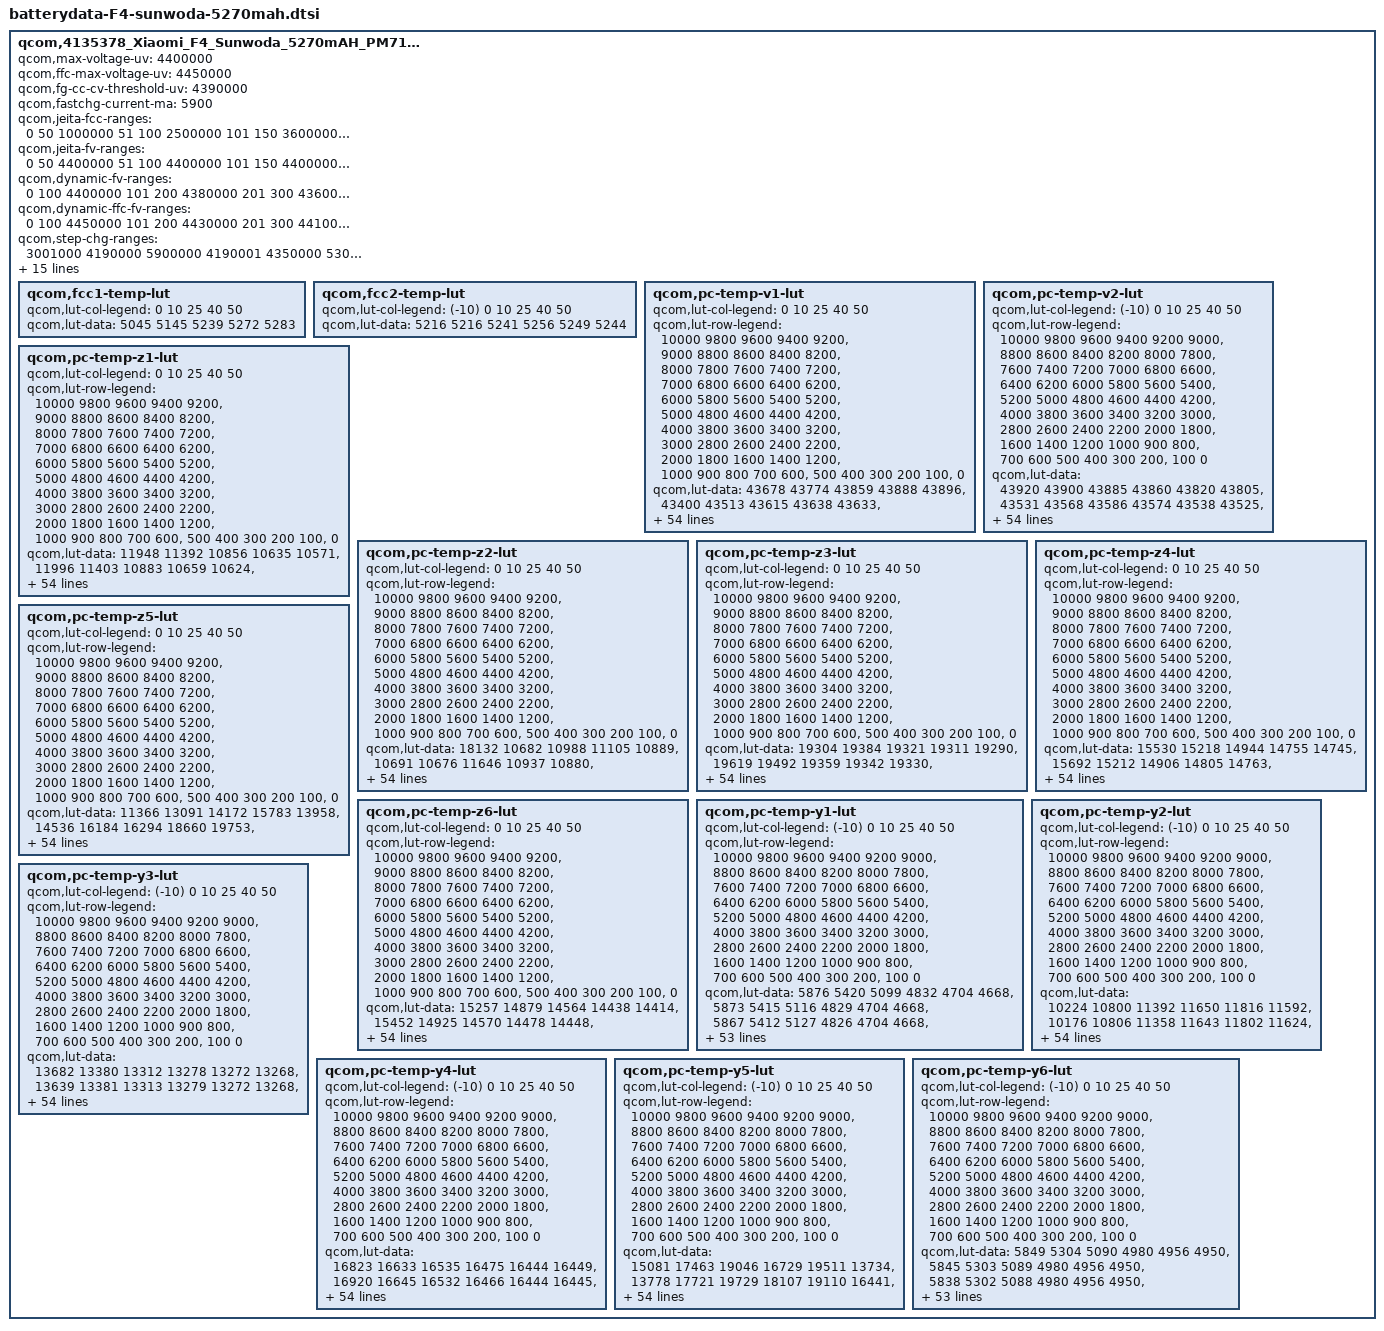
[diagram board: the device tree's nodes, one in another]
qcom,4135378_Xiaomi_F4_Sunwoda_5270mAH_PM7150 {
	/* 4135378_Xiaomi_F4_Sunwoda_5270mAH_PM7150_averaged_MasterSlave_Aug12th2019 */
	qcom,max-voltage-uv = <4400000>;
	qcom,ffc-max-voltage-uv = <4450000>;
	qcom,fg-cc-cv-threshold-uv = <4390000>;
	qcom,fastchg-current-ma = <5900>;
	qcom,jeita-fcc-ranges = <0  50   1000000
				51  100  2500000
				101 150  3600000
				151 480  5900000
				481 580  2800000>;
	qcom,jeita-fv-ranges = <0   50  4400000
				51  100  4400000
				101 150  4400000
				151 480  4450000
				481 580  4100000>;
	qcom,dynamic-fv-ranges = <0    100  4400000
				101  200  4380000
				201  300  4360000
				301  400  4340000
				401  500  4340000>;
	qcom,dynamic-ffc-fv-ranges = <0    100  4450000
				101  200  4430000
				201  300  4410000
				301  400  4390000
				401  500  4390000>;
	qcom,step-chg-ranges = <3001000  4190000  5900000
				4190001  4350000  5300000
				4350001  4390000  5300000
				4390001  4430000  4100000
				4430001  4480000  4100000>;
	qcom,temp-comp-ranges = <0    3899  0
				 3900 4599  2
				 4600 5599  5
				 5600 5749  6
				 5750 5900  6>;
	qcom,nom-batt-capacity-mah = <5260>;
	qcom,batt-id-kohm = <100>;
	qcom,battery-beta = <4250>;
	qcom,battery-therm-kohm = <100>;
	qcom,battery-type = "f4_swd";
	qcom,qg-batt-profile-ver = <100>;
	qcom,temp-comp-enable;
	qcom,temp-comp-hysteresis = <200>;
	qcom,max-temp-comp-value = <6>;
	mi,six-pin-battery;
	mi,use-bq-pump;
	mi,fcc-limited-by-soc;
	mi,ffc-iterm-change-by-temp;
	qcom,fcc1-temp-lut {
		qcom,lut-col-legend = <0 10 25 40 50>;
		qcom,lut-data = <5045 5145 5239 5272 5283>;
	};

	qcom,fcc2-temp-lut {
		qcom,lut-col-legend = <(-10) 0 10 25 40 50>;
		qcom,lut-data = <5216 5216 5241 5256 5249 5244>;
	};

	qcom,pc-temp-v1-lut {
		qcom,lut-col-legend = <0 10 25 40 50>;
		qcom,lut-row-legend = <10000 9800 9600 9400 9200>,
			<9000 8800 8600 8400 8200>,
			<8000 7800 7600 7400 7200>,
			<7000 6800 6600 6400 6200>,
			<6000 5800 5600 5400 5200>,
			<5000 4800 4600 4400 4200>,
			<4000 3800 3600 3400 3200>,
			<3000 2800 2600 2400 2200>,
			<2000 1800 1600 1400 1200>,
			<1000 900 800 700 600>,
			<500 400 300 200 100>,
			<0>;
		qcom,lut-data = <43678 43774 43859 43888 43896>,
			<43400 43513 43615 43638 43633>,
			<43145 43263 43372 43392 43392>,
			<42901 43024 43132 43152 43155>,
			<42662 42788 42893 42918 42925>,
			<42431 42551 42655 42685 42697>,
			<42205 42318 42417 42451 42465>,
			<41985 42091 42181 42218 42233>,
			<41769 41871 41951 41989 42004>,
			<41558 41654 41726 41762 41775>,
			<41351 41437 41506 41539 41549>,
			<41152 41225 41291 41318 41328>,
			<40971 41030 41080 41101 41110>,
			<40790 40857 40877 40895 40903>,
			<40573 40678 40678 40697 40702>,
			<40309 40457 40481 40505 40509>,
			<40076 40213 40275 40308 40317>,
			<39915 40016 40081 40117 40132>,
			<39782 39873 39921 39944 39959>,
			<39651 39739 39787 39795 39803>,
			<39526 39580 39627 39635 39638>,
			<39399 39406 39394 39426 39433>,
			<39254 39223 39151 39199 39210>,
			<39094 39003 38978 39014 39024>,
			<38934 38799 38839 38858 38865>,
			<38765 38687 38719 38724 38727>,
			<38609 38618 38613 38610 38610>,
			<38513 38554 38519 38511 38508>,
			<38449 38486 38432 38419 38414>,
			<38398 38420 38352 38333 38325>,
			<38354 38360 38282 38257 38245>,
			<38317 38302 38216 38187 38172>,
			<38281 38250 38160 38125 38105>,
			<38247 38205 38112 38070 38046>,
			<38215 38166 38072 38025 37995>,
			<38183 38129 38032 37978 37942>,
			<38154 38098 37994 37926 37882>,
			<38116 38061 37953 37869 37817>,
			<38056 37999 37892 37801 37741>,
			<37977 37905 37805 37718 37652>,
			<37884 37804 37706 37622 37552>,
			<37769 37693 37596 37510 37442>,
			<37634 37564 37468 37381 37315>,
			<37473 37401 37308 37226 37151>,
			<37324 37251 37164 37084 37015>,
			<37237 37156 37068 36996 36937>,
			<37208 37130 37044 36969 36911>,
			<37181 37109 37028 36951 36894>,
			<37156 37088 37009 36933 36877>,
			<37110 37042 36958 36870 36798>,
			<36918 36804 36693 36576 36485>,
			<36484 36362 36255 36135 36044>,
			<35926 35792 35681 35561 35469>,
			<35171 35012 34898 34778 34687>,
			<33988 33780 33676 33557 33461>,
			<30000 30000 30000 30000 30000>;
	};

	qcom,pc-temp-v2-lut {
		qcom,lut-col-legend = <(-10) 0 10 25 40 50>;
		qcom,lut-row-legend = <10000 9800 9600 9400 9200 9000>,
			<8800 8600 8400 8200 8000 7800>,
			<7600 7400 7200 7000 6800 6600>,
			<6400 6200 6000 5800 5600 5400>,
			<5200 5000 4800 4600 4400 4200>,
			<4000 3800 3600 3400 3200 3000>,
			<2800 2600 2400 2200 2000 1800>,
			<1600 1400 1200 1000 900 800>,
			<700 600 500 400 300 200>,
			<100 0>;
		qcom,lut-data = <43920 43900 43885 43860 43820 43805>,
			<43531 43568 43586 43574 43538 43525>,
			<43181 43260 43305 43303 43271 43259>,
			<42873 42980 43043 43047 43018 43008>,
			<42599 42728 42799 42807 42779 42772>,
			<42354 42486 42561 42572 42545 42539>,
			<42145 42242 42324 42336 42311 42305>,
			<41949 42004 42090 42102 42079 42073>,
			<41715 41780 41861 41872 41850 41844>,
			<41411 41568 41637 41645 41624 41618>,
			<41174 41362 41417 41421 41401 41396>,
			<41083 41161 41206 41201 41183 41177>,
			<41021 40962 41000 40985 40969 40963>,
			<40870 40758 40795 40779 40764 40758>,
			<40411 40548 40590 40581 40565 40559>,
			<39937 40326 40385 40386 40371 40367>,
			<39675 40063 40178 40183 40178 40179>,
			<39475 39779 39971 39982 39990 39997>,
			<39288 39550 39765 39804 39815 39824>,
			<39115 39375 39556 39653 39660 39664>,
			<38951 39213 39352 39488 39492 39493>,
			<38782 39038 39152 39265 39272 39275>,
			<38616 38862 38959 39022 39030 39037>,
			<38481 38705 38795 38835 38842 38849>,
			<38373 38567 38654 38686 38693 38700>,
			<38282 38441 38528 38559 38565 38571>,
			<38205 38316 38413 38446 38453 38457>,
			<38140 38197 38310 38345 38354 38356>,
			<38082 38104 38217 38254 38263 38264>,
			<38031 38035 38135 38169 38179 38178>,
			<37984 37979 38060 38092 38102 38100>,
			<37937 37934 37984 38021 38032 38030>,
			<37892 37897 37912 37956 37968 37964>,
			<37845 37861 37856 37893 37902 37896>,
			<37797 37826 37818 37834 37838 37827>,
			<37746 37791 37780 37772 37767 37749>,
			<37693 37753 37736 37704 37673 37643>,
			<37636 37715 37689 37632 37563 37517>,
			<37570 37664 37631 37558 37470 37413>,
			<37491 37583 37564 37484 37394 37332>,
			<37402 37481 37484 37404 37316 37253>,
			<37308 37377 37385 37309 37222 37158>,
			<37208 37263 37265 37197 37114 37051>,
			<37119 37134 37122 37060 36978 36916>,
			<37036 37002 36992 36944 36871 36811>,
			<36947 36904 36915 36888 36822 36767>,
			<36897 36867 36893 36871 36812 36757>,
			<36844 36825 36869 36856 36795 36743>,
			<36779 36777 36834 36822 36765 36709>,
			<36665 36682 36746 36730 36656 36579>,
			<36440 36477 36485 36416 36334 36240>,
			<36031 36079 35997 35920 35836 35732>,
			<35439 35500 35347 35265 35189 35080>,
			<34575 34707 34439 34354 34277 34166>,
			<33147 33458 33057 32923 32954 32792>,
			<29769 30982 28076 28062 28203 28233>;
	};

	qcom,pc-temp-z1-lut {
		qcom,lut-col-legend = <0 10 25 40 50>;
		qcom,lut-row-legend = <10000 9800 9600 9400 9200>,
			<9000 8800 8600 8400 8200>,
			<8000 7800 7600 7400 7200>,
			<7000 6800 6600 6400 6200>,
			<6000 5800 5600 5400 5200>,
			<5000 4800 4600 4400 4200>,
			<4000 3800 3600 3400 3200>,
			<3000 2800 2600 2400 2200>,
			<2000 1800 1600 1400 1200>,
			<1000 900 800 700 600>,
			<500 400 300 200 100>,
			<0>;
		qcom,lut-data = <11948 11392 10856 10635 10571>,
			<11996 11403 10883 10659 10624>,
			<12017 11405 10898 10691 10638>,
			<12027 11405 10895 10699 10641>,
			<12010 11403 10889 10698 10643>,
			<11979 11392 10884 10697 10643>,
			<11967 11377 10879 10696 10643>,
			<11968 11368 10875 10696 10643>,
			<11968 11360 10872 10695 10643>,
			<11963 11352 10871 10694 10642>,
			<11948 11346 10871 10694 10642>,
			<11931 11339 10871 10694 10642>,
			<11905 11330 10872 10694 10642>,
			<11876 11316 10871 10694 10642>,
			<11852 11306 10867 10693 10642>,
			<11827 11304 10864 10692 10642>,
			<11814 11302 10863 10692 10643>,
			<11820 11301 10862 10693 10643>,
			<11833 11304 10863 10694 10644>,
			<11841 11309 10866 10695 10645>,
			<11845 11314 10869 10697 10646>,
			<11846 11321 10871 10697 10647>,
			<11845 11324 10873 10698 10647>,
			<11844 11324 10875 10699 10648>,
			<11846 11323 10879 10701 10650>,
			<11856 11325 10883 10704 10652>,
			<11865 11328 10886 10706 10654>,
			<11869 11334 10889 10709 10657>,
			<11871 11345 10893 10712 10659>,
			<11871 11359 10897 10714 10661>,
			<11867 11362 10900 10716 10663>,
			<11861 11363 10904 10719 10665>,
			<11860 11364 10907 10721 10667>,
			<11869 11366 10911 10723 10669>,
			<11881 11371 10915 10726 10671>,
			<11889 11374 10919 10729 10674>,
			<11896 11377 10926 10732 10676>,
			<11903 11382 10933 10735 10677>,
			<11909 11390 10938 10738 10679>,
			<11916 11402 10942 10741 10681>,
			<11929 11411 10946 10743 10683>,
			<11957 11416 10951 10745 10685>,
			<11972 11423 10956 10747 10687>,
			<11978 11431 10960 10749 10688>,
			<11985 11449 10963 10752 10690>,
			<11988 11452 10965 10753 10690>,
			<11975 11452 10970 10754 10691>,
			<11985 11455 10969 10754 10692>,
			<11986 11434 10972 10756 10693>,
			<11993 11451 10978 10759 10695>,
			<11990 11465 10983 10763 10699>,
			<12011 11469 10987 10769 10704>,
			<12021 11496 11003 10776 10710>,
			<12027 11519 11017 10785 10718>,
			<12027 11519 11017 10785 10718>,
			<12027 11519 11017 10785 10718>;
	};

	qcom,pc-temp-z2-lut {
		qcom,lut-col-legend = <0 10 25 40 50>;
		qcom,lut-row-legend = <10000 9800 9600 9400 9200>,
			<9000 8800 8600 8400 8200>,
			<8000 7800 7600 7400 7200>,
			<7000 6800 6600 6400 6200>,
			<6000 5800 5600 5400 5200>,
			<5000 4800 4600 4400 4200>,
			<4000 3800 3600 3400 3200>,
			<3000 2800 2600 2400 2200>,
			<2000 1800 1600 1400 1200>,
			<1000 900 800 700 600>,
			<500 400 300 200 100>,
			<0>;
		qcom,lut-data = <18132 10682 10988 11105 10889>,
			<10691 10676 11646 10937 10880>,
			<10509 10660 11990 11057 11019>,
			<10450 10634 11936 11200 11056>,
			<10417 10607 11694 11653 10988>,
			<10397 10576 11437 11962 10907>,
			<10386 10548 11120 11667 10837>,
			<10379 10536 10882 11154 10761>,
			<10374 10529 10980 11068 10743>,
			<10370 10526 11320 11421 10759>,
			<10365 10535 11471 11706 10779>,
			<10363 10562 11457 11754 10794>,
			<10369 10627 11434 11793 10810>,
			<10379 10880 11423 11791 10830>,
			<10387 11086 11414 11732 10862>,
			<10395 10996 11411 11689 10883>,
			<10407 10770 11427 11719 10878>,
			<10426 10688 11446 11771 10868>,
			<10454 10715 11370 11711 10871>,
			<10483 10752 11110 11261 10926>,
			<10517 10780 10998 10960 10992>,
			<10546 10806 11070 11055 11041>,
			<10565 10815 11145 11191 11089>,
			<10580 10802 11143 11244 11139>,
			<10589 10785 11103 11261 11212>,
			<10593 10782 11080 11257 11256>,
			<10597 10786 11088 11193 11126>,
			<10605 10790 11099 11083 10875>,
			<10623 10794 11082 11011 10780>,
			<10641 10797 11022 10946 10746>,
			<10652 10799 10988 10911 10732>,
			<10661 10800 10992 10911 10746>,
			<10671 10801 11004 10916 10780>,
			<10681 10807 11018 10914 10815>,
			<10693 10819 11043 10909 10855>,
			<10705 10828 11066 10906 10904>,
			<10719 10834 11084 10979 10981>,
			<10733 10841 11101 11116 11063>,
			<10746 10858 11128 11198 11088>,
			<10760 10885 11170 11259 11093>,
			<10778 10899 11197 11286 11095>,
			<10799 10902 11198 11270 11098>,
			<10825 10907 11194 11233 11100>,
			<10862 10928 11199 11156 11079>,
			<11203 11095 11252 11125 11040>,
			<11335 11201 11270 11179 11033>,
			<11367 11228 11239 11152 11077>,
			<11318 11259 11208 11146 11052>,
			<11300 11273 11220 11190 11180>,
			<11257 11319 11301 11388 11246>,
			<11226 11354 11393 11038 10832>,
			<11043 11362 11430 10923 10748>,
			<10808 11444 11285 10853 10683>,
			<10566 11338 11164 10765 10620>,
			<10566 11338 11164 10765 10620>,
			<10566 11338 11164 10765 10620>;
	};

	qcom,pc-temp-z3-lut {
		qcom,lut-col-legend = <0 10 25 40 50>;
		qcom,lut-row-legend = <10000 9800 9600 9400 9200>,
			<9000 8800 8600 8400 8200>,
			<8000 7800 7600 7400 7200>,
			<7000 6800 6600 6400 6200>,
			<6000 5800 5600 5400 5200>,
			<5000 4800 4600 4400 4200>,
			<4000 3800 3600 3400 3200>,
			<3000 2800 2600 2400 2200>,
			<2000 1800 1600 1400 1200>,
			<1000 900 800 700 600>,
			<500 400 300 200 100>,
			<0>;
		qcom,lut-data = <19304 19384 19321 19311 19290>,
			<19619 19492 19359 19342 19330>,
			<19671 19520 19386 19350 19339>,
			<19689 19529 19399 19359 19343>,
			<19696 19533 19409 19371 19345>,
			<19701 19535 19412 19377 19346>,
			<19701 19536 19406 19370 19345>,
			<19697 19535 19400 19358 19342>,
			<19691 19529 19401 19354 19339>,
			<19687 19522 19406 19357 19337>,
			<19683 19515 19407 19359 19335>,
			<19677 19507 19400 19358 19334>,
			<19662 19506 19393 19357 19333>,
			<19646 19511 19393 19355 19331>,
			<19644 19515 19393 19351 19327>,
			<19646 19509 19393 19347 19324>,
			<19648 19494 19393 19345 19322>,
			<19639 19482 19391 19344 19321>,
			<19620 19473 19385 19340 19320>,
			<19607 19468 19368 19329 19316>,
			<19597 19470 19360 19323 19314>,
			<19591 19478 19369 19325 19315>,
			<19594 19482 19379 19330 19320>,
			<19606 19482 19377 19333 19326>,
			<19613 19481 19366 19335 19337>,
			<19615 19479 19360 19337 19343>,
			<19615 19473 19370 19344 19344>,
			<19613 19470 19384 19353 19344>,
			<19609 19471 19389 19354 19343>,
			<19604 19473 19391 19352 19341>,
			<19598 19475 19391 19348 19338>,
			<19591 19477 19389 19346 19335>,
			<19585 19478 19386 19343 19332>,
			<19579 19477 19383 19339 19328>,
			<19574 19474 19379 19335 19323>,
			<19570 19470 19375 19332 19320>,
			<19566 19466 19372 19331 19318>,
			<19563 19462 19370 19331 19318>,
			<19561 19461 19367 19330 19318>,
			<19558 19459 19366 19329 19320>,
			<19555 19457 19364 19328 19322>,
			<19547 19453 19362 19328 19321>,
			<19539 19448 19360 19329 19320>,
			<19530 19444 19359 19326 19324>,
			<19476 19424 19351 19324 19324>,
			<19358 19405 19346 19315 19313>,
			<19306 19395 19341 19315 19310>,
			<19299 19391 19335 19313 19309>,
			<19293 19387 19334 19309 19298>,
			<19291 19388 19327 19301 19300>,
			<19294 19385 19322 19324 19321>,
			<19298 19375 19319 19328 19322>,
			<19297 19340 19329 19329 19323>,
			<19302 19320 19330 19330 19319>,
			<19302 19320 19330 19330 19319>,
			<19302 19320 19330 19330 19319>;
	};

	qcom,pc-temp-z4-lut {
		qcom,lut-col-legend = <0 10 25 40 50>;
		qcom,lut-row-legend = <10000 9800 9600 9400 9200>,
			<9000 8800 8600 8400 8200>,
			<8000 7800 7600 7400 7200>,
			<7000 6800 6600 6400 6200>,
			<6000 5800 5600 5400 5200>,
			<5000 4800 4600 4400 4200>,
			<4000 3800 3600 3400 3200>,
			<3000 2800 2600 2400 2200>,
			<2000 1800 1600 1400 1200>,
			<1000 900 800 700 600>,
			<500 400 300 200 100>,
			<0>;
		qcom,lut-data = <15530 15218 14944 14755 14745>,
			<15692 15212 14906 14805 14763>,
			<15560 15174 14868 14786 14753>,
			<15411 15052 14826 14764 14742>,
			<15285 14944 14781 14729 14727>,
			<15164 14883 14754 14704 14713>,
			<15073 14835 14740 14698 14701>,
			<15004 14800 14729 14695 14691>,
			<14948 14772 14711 14691 14685>,
			<14905 14751 14684 14677 14681>,
			<14870 14736 14671 14665 14678>,
			<14840 14725 14669 14659 14674>,
			<14810 14707 14668 14655 14670>,
			<14787 14676 14665 14652 14666>,
			<14779 14655 14659 14648 14662>,
			<14775 14668 14653 14645 14659>,
			<14772 14702 14648 14642 14655>,
			<14763 14713 14644 14639 14652>,
			<14751 14696 14643 14639 14649>,
			<14739 14678 14647 14643 14648>,
			<14725 14678 14655 14650 14647>,
			<14715 14687 14687 14676 14665>,
			<14716 14700 14727 14712 14700>,
			<14720 14746 14746 14723 14708>,
			<14727 14795 14758 14725 14702>,
			<14756 14799 14763 14726 14695>,
			<14793 14783 14744 14713 14686>,
			<14799 14766 14715 14690 14677>,
			<14791 14750 14699 14679 14670>,
			<14780 14735 14688 14673 14665>,
			<14769 14723 14681 14669 14661>,
			<14757 14712 14677 14665 14657>,
			<14747 14703 14675 14662 14654>,
			<14737 14698 14673 14660 14652>,
			<14728 14694 14671 14658 14651>,
			<14719 14690 14669 14657 14651>,
			<14711 14686 14669 14659 14654>,
			<14704 14683 14668 14663 14659>,
			<14698 14684 14669 14665 14661>,
			<14694 14686 14673 14667 14662>,
			<14693 14687 14675 14668 14662>,
			<14693 14681 14667 14662 14657>,
			<14692 14674 14660 14655 14650>,
			<14686 14670 14659 14657 14651>,
			<14680 14657 14651 14651 14645>,
			<14786 14657 14643 14646 14638>,
			<14840 14660 14641 14639 14634>,
			<14844 14658 14636 14629 14624>,
			<14844 14657 14630 14621 14619>,
			<14841 14651 14636 14627 14617>,
			<14839 14664 14657 14624 14621>,
			<14851 14681 14664 14623 14622>,
			<14861 14725 14654 14623 14621>,
			<14866 14753 14656 14624 14625>,
			<14866 14753 14656 14624 14625>,
			<14866 14753 14656 14624 14625>;
	};

	qcom,pc-temp-z5-lut {
		qcom,lut-col-legend = <0 10 25 40 50>;
		qcom,lut-row-legend = <10000 9800 9600 9400 9200>,
			<9000 8800 8600 8400 8200>,
			<8000 7800 7600 7400 7200>,
			<7000 6800 6600 6400 6200>,
			<6000 5800 5600 5400 5200>,
			<5000 4800 4600 4400 4200>,
			<4000 3800 3600 3400 3200>,
			<3000 2800 2600 2400 2200>,
			<2000 1800 1600 1400 1200>,
			<1000 900 800 700 600>,
			<500 400 300 200 100>,
			<0>;
		qcom,lut-data = <11366 13091 14172 15783 13958>,
			<14536 16184 16294 18660 19753>,
			<15429 17677 18039 20091 21589>,
			<16046 18486 19409 21864 22244>,
			<16686 19327 20835 24539 22637>,
			<17237 20522 21530 26090 22838>,
			<17808 21771 21882 25382 23035>,
			<18377 22742 22282 24101 23435>,
			<18991 23483 24363 24114 23693>,
			<19832 24296 29555 26778 23909>,
			<20852 25304 31712 29535 24194>,
			<21372 26581 30664 31332 24784>,
			<21466 28831 29503 32882 25538>,
			<21550 34455 29919 33139 25672>,
			<22370 38743 31851 32223 25165>,
			<25743 36093 33871 31620 24755>,
			<28124 29568 36471 32583 25378>,
			<27371 27226 38585 34187 26764>,
			<25874 28656 37287 34288 27609>,
			<25473 31450 32317 30907 28171>,
			<26710 38603 30062 28400 28455>,
			<28982 52810 35982 28320 28114>,
			<35077 59126 43048 28068 27206>,
			<48373 53997 40380 26986 26022>,
			<56450 45792 28220 22860 23884>,
			<57720 39535 22073 20071 22497>,
			<57330 33508 23472 21522 23235>,
			<55353 30742 26047 24446 24993>,
			<51369 31115 28865 26478 26614>,
			<47257 32036 32560 27903 28195>,
			<44071 33653 35967 29386 29792>,
			<41223 37527 39508 31438 31535>,
			<39384 40984 42568 33545 33190>,
			<38052 42868 43722 34739 34076>,
			<37248 44435 44485 35482 34648>,
			<37237 44725 44779 36017 34902>,
			<37522 43797 43956 36483 34538>,
			<37981 42814 42277 36827 33730>,
			<40100 42649 40131 36229 32996>,
			<42923 42760 36891 32505 32252>,
			<42812 42310 34681 29990 31595>,
			<38232 39014 34015 30629 30995>,
			<36748 36699 33385 31314 30646>,
			<37941 36555 31710 27886 33486>,
			<33457 37206 30800 27541 34047>,
			<19015 31020 30238 23680 25791>,
			<13019 25980 28126 24406 24839>,
			<12789 25058 25363 26257 27986>,
			<12659 23974 26366 27783 25096>,
			<12643 25356 23064 21669 26269>,
			<12774 23117 18722 28707 33198>,
			<12692 19468 17125 28914 30754>,
			<12485 15338 18728 28017 29148>,
			<12399 13697 18378 26355 22642>,
			<12399 13697 18378 26355 22642>,
			<12399 13697 18378 26355 22642>;
	};

	qcom,pc-temp-z6-lut {
		qcom,lut-col-legend = <0 10 25 40 50>;
		qcom,lut-row-legend = <10000 9800 9600 9400 9200>,
			<9000 8800 8600 8400 8200>,
			<8000 7800 7600 7400 7200>,
			<7000 6800 6600 6400 6200>,
			<6000 5800 5600 5400 5200>,
			<5000 4800 4600 4400 4200>,
			<4000 3800 3600 3400 3200>,
			<3000 2800 2600 2400 2200>,
			<2000 1800 1600 1400 1200>,
			<1000 900 800 700 600>,
			<500 400 300 200 100>,
			<0>;
		qcom,lut-data = <15257 14879 14564 14438 14414>,
			<15452 14925 14570 14478 14448>,
			<15401 14917 14571 14480 14452>,
			<15339 14860 14566 14479 14453>,
			<15275 14808 14549 14473 14448>,
			<15205 14777 14534 14464 14442>,
			<15150 14751 14525 14457 14436>,
			<15106 14729 14516 14449 14430>,
			<15069 14709 14508 14444 14426>,
			<15041 14693 14499 14440 14423>,
			<15018 14682 14493 14437 14421>,
			<14994 14673 14489 14434 14418>,
			<14962 14662 14485 14431 14416>,
			<14932 14647 14482 14428 14413>,
			<14919 14638 14480 14424 14409>,
			<14912 14639 14477 14420 14406>,
			<14906 14642 14475 14418 14403>,
			<14896 14643 14472 14416 14401>,
			<14884 14632 14468 14414 14399>,
			<14875 14621 14462 14411 14396>,
			<14866 14623 14459 14409 14395>,
			<14861 14631 14479 14420 14403>,
			<14863 14642 14503 14439 14421>,
			<14872 14664 14508 14447 14429>,
			<14883 14685 14509 14450 14432>,
			<14899 14686 14509 14451 14433>,
			<14916 14678 14507 14449 14431>,
			<14918 14670 14503 14445 14428>,
			<14914 14665 14500 14441 14424>,
			<14909 14661 14496 14438 14421>,
			<14902 14658 14494 14435 14418>,
			<14895 14655 14491 14432 14415>,
			<14889 14653 14489 14429 14412>,
			<14884 14652 14487 14426 14409>,
			<14880 14650 14485 14423 14406>,
			<14878 14649 14483 14422 14404>,
			<14877 14647 14482 14422 14405>,
			<14876 14646 14481 14424 14406>,
			<14877 14648 14482 14425 14407>,
			<14880 14653 14483 14425 14409>,
			<14883 14654 14484 14425 14410>,
			<14886 14652 14481 14424 14408>,
			<14887 14651 14477 14421 14405>,
			<14887 14651 14477 14421 14407>,
			<14867 14642 14471 14418 14405>,
			<14856 14633 14466 14411 14397>,
			<14854 14631 14462 14408 14393>,
			<14852 14628 14458 14403 14388>,
			<14851 14627 14455 14397 14381>,
			<14853 14628 14455 14396 14380>,
			<14859 14636 14463 14408 14395>,
			<14873 14643 14466 14411 14397>,
			<14886 14650 14470 14413 14400>,
			<14905 14661 14474 14416 14401>,
			<14905 14661 14474 14416 14401>,
			<14905 14661 14474 14416 14401>;
	};

	qcom,pc-temp-y1-lut {
		qcom,lut-col-legend = <(-10) 0 10 25 40 50>;
		qcom,lut-row-legend = <10000 9800 9600 9400 9200 9000>,
			<8800 8600 8400 8200 8000 7800>,
			<7600 7400 7200 7000 6800 6600>,
			<6400 6200 6000 5800 5600 5400>,
			<5200 5000 4800 4600 4400 4200>,
			<4000 3800 3600 3400 3200 3000>,
			<2800 2600 2400 2200 2000 1800>,
			<1600 1400 1200 1000 900 800>,
			<700 600 500 400 300 200>,
			<100 0>;
		qcom,lut-data = <5876 5420 5099 4832 4704 4668>,
			<5873 5415 5116 4829 4704 4668>,
			<5867 5412 5127 4826 4704 4668>,
			<5859 5412 5133 4823 4704 4668>,
			<5853 5412 5136 4821 4703 4668>,
			<5851 5412 5136 4819 4702 4668>,
			<5852 5417 5132 4818 4701 4668>,
			<5853 5426 5124 4816 4700 4668>,
			<5856 5427 5117 4815 4699 4668>,
			<5870 5423 5109 4814 4699 4667>,
			<5879 5419 5103 4813 4698 4667>,
			<5870 5417 5099 4812 4698 4667>,
			<5855 5413 5095 4811 4697 4666>,
			<5853 5415 5094 4810 4697 4666>,
			<5869 5418 5095 4810 4697 4667>,
			<5883 5421 5095 4810 4698 4667>,
			<5875 5430 5098 4810 4698 4667>,
			<5856 5443 5102 4810 4699 4668>,
			<5849 5446 5103 4810 4699 4668>,
			<5849 5433 5102 4811 4699 4668>,
			<5848 5421 5101 4813 4699 4668>,
			<5844 5420 5098 4814 4700 4668>,
			<5834 5420 5093 4816 4701 4668>,
			<5831 5419 5093 4817 4702 4669>,
			<5851 5416 5100 4818 4702 4669>,
			<5870 5413 5106 4819 4703 4670>,
			<5861 5417 5109 4821 4704 4671>,
			<5832 5429 5111 4823 4706 4672>,
			<5820 5434 5111 4825 4707 4673>,
			<5835 5438 5110 4828 4708 4674>,
			<5850 5441 5111 4832 4710 4675>,
			<5845 5439 5114 4835 4711 4677>,
			<5828 5433 5120 4839 4713 4679>,
			<5820 5431 5127 4842 4715 4680>,
			<5840 5438 5135 4844 4716 4681>,
			<5862 5446 5141 4846 4717 4682>,
			<5863 5444 5140 4848 4718 4683>,
			<5853 5433 5139 4849 4720 4684>,
			<5844 5428 5138 4851 4721 4685>,
			<5847 5431 5140 4852 4722 4686>,
			<5855 5436 5142 4854 4723 4687>,
			<5855 5437 5146 4856 4724 4688>,
			<5854 5438 5153 4858 4726 4689>,
			<5853 5434 5153 4863 4728 4690>,
			<5852 5424 5158 4869 4730 4691>,
			<5857 5429 5181 4873 4732 4693>,
			<5892 5450 5182 4872 4733 4693>,
			<5855 5456 5171 4876 4733 4693>,
			<5887 5467 5170 4876 4733 4693>,
			<5883 5454 5180 4878 4733 4693>,
			<5912 5451 5181 4880 4735 4695>,
			<5887 5463 5186 4888 4739 4698>,
			<5894 5467 5214 4896 4744 4702>,
			<5912 5495 5224 4910 4750 4707>,
			<5912 5495 5224 4910 4750 4707>,
			<5912 5495 5224 4910 4750 4707>;
	};

	qcom,pc-temp-y2-lut {
		qcom,lut-col-legend = <(-10) 0 10 25 40 50>;
		qcom,lut-row-legend = <10000 9800 9600 9400 9200 9000>,
			<8800 8600 8400 8200 8000 7800>,
			<7600 7400 7200 7000 6800 6600>,
			<6400 6200 6000 5800 5600 5400>,
			<5200 5000 4800 4600 4400 4200>,
			<4000 3800 3600 3400 3200 3000>,
			<2800 2600 2400 2200 2000 1800>,
			<1600 1400 1200 1000 900 800>,
			<700 600 500 400 300 200>,
			<100 0>;
		qcom,lut-data = <10224 10800 11392 11650 11816 11592>,
			<10176 10806 11358 11643 11802 11624>,
			<10157 10813 11325 11639 11759 11641>,
			<10161 10820 11293 11636 11702 11647>,
			<10180 10825 11265 11636 11645 11644>,
			<10208 10829 11239 11635 11602 11638>,
			<10245 10832 11214 11613 11558 11610>,
			<10301 10833 11193 11577 11513 11564>,
			<10408 10832 11184 11560 11501 11533>,
			<10669 10824 11179 11516 11495 11511>,
			<10849 10818 11176 11487 11492 11495>,
			<10780 10884 11168 11487 11523 11476>,
			<10643 11028 11160 11488 11575 11452>,
			<10622 11121 11170 11485 11565 11427>,
			<10779 11188 11253 11472 11432 11380>,
			<10910 11224 11345 11465 11337 11349>,
			<10628 11218 11414 11509 11400 11362>,
			<10004 11203 11471 11599 11536 11395>,
			<9765 11201 11483 11686 11650 11440>,
			<9728 11232 11473 11790 11768 11524>,
			<9708 11274 11466 11847 11833 11605>,
			<9697 11305 11482 11808 11793 11656>,
			<9689 11334 11519 11739 11720 11698>,
			<9685 11362 11551 11727 11704 11730>,
			<9683 11390 11582 11756 11731 11758>,
			<9681 11414 11610 11789 11761 11779>,
			<9679 11432 11632 11817 11782 11778>,
			<9677 11447 11650 11845 11806 11763>,
			<9676 11453 11663 11875 11842 11776>,
			<9674 11453 11671 11918 11909 11839>,
			<9672 11452 11679 11947 11961 11896>,
			<9670 11432 11688 11953 11975 11919>,
			<9668 11367 11698 11957 11978 11940>,
			<9667 11312 11698 11962 11976 11947>,
			<9666 11278 11676 11974 11972 11954>,
			<9665 11245 11645 11983 11963 11953>,
			<9664 11206 11620 11954 11918 11932>,
			<9663 11160 11592 11900 11841 11895>,
			<9662 11075 11556 11885 11815 11856>,
			<9662 10548 11505 11886 11814 11812>,
			<9661 9911 11443 11886 11814 11765>,
			<9661 9752 11372 11836 11808 11710>,
			<9661 9704 11290 11768 11799 11665>,
			<9660 9686 11202 11787 11802 11676>,
			<9660 9678 11086 11754 11773 11654>,
			<9659 9671 10994 11678 11600 11474>,
			<9659 9671 10969 11649 11514 11406>,
			<9659 9668 10918 11652 11492 11349>,
			<9659 9666 10875 11605 11504 11347>,
			<9658 9663 10829 11598 11518 11350>,
			<9657 9661 10747 11589 11488 11337>,
			<9657 9659 10613 11500 11433 11271>,
			<9656 9657 10471 11395 11312 11135>,
			<9654 9656 10071 11286 11138 10954>,
			<9654 9656 10071 11286 11138 10954>,
			<9654 9656 10071 11286 11138 10954>;
	};

	qcom,pc-temp-y3-lut {
		qcom,lut-col-legend = <(-10) 0 10 25 40 50>;
		qcom,lut-row-legend = <10000 9800 9600 9400 9200 9000>,
			<8800 8600 8400 8200 8000 7800>,
			<7600 7400 7200 7000 6800 6600>,
			<6400 6200 6000 5800 5600 5400>,
			<5200 5000 4800 4600 4400 4200>,
			<4000 3800 3600 3400 3200 3000>,
			<2800 2600 2400 2200 2000 1800>,
			<1600 1400 1200 1000 900 800>,
			<700 600 500 400 300 200>,
			<100 0>;
		qcom,lut-data = <13682 13380 13312 13278 13272 13268>,
			<13639 13381 13313 13279 13272 13268>,
			<13613 13382 13315 13280 13272 13269>,
			<13599 13384 13316 13282 13272 13271>,
			<13594 13385 13317 13283 13272 13271>,
			<13593 13386 13318 13283 13272 13272>,
			<13605 13387 13319 13283 13272 13272>,
			<13627 13389 13319 13283 13273 13272>,
			<13620 13391 13320 13283 13273 13272>,
			<13535 13400 13321 13283 13273 13272>,
			<13468 13406 13321 13283 13274 13273>,
			<13465 13401 13322 13283 13275 13273>,
			<13463 13392 13324 13283 13278 13273>,
			<13463 13384 13324 13284 13279 13274>,
			<13463 13377 13325 13289 13279 13276>,
			<13462 13372 13325 13291 13280 13278>,
			<13445 13370 13325 13291 13280 13277>,
			<13407 13368 13323 13290 13281 13277>,
			<13393 13365 13320 13290 13281 13277>,
			<13392 13359 13317 13291 13281 13278>,
			<13393 13352 13314 13292 13282 13278>,
			<13393 13347 13311 13290 13279 13277>,
			<13393 13343 13308 13286 13275 13273>,
			<13391 13338 13306 13284 13273 13272>,
			<13383 13334 13304 13283 13272 13271>,
			<13375 13330 13302 13282 13272 13270>,
			<13377 13324 13301 13281 13272 13270>,
			<13384 13317 13300 13281 13273 13270>,
			<13393 13314 13300 13281 13273 13270>,
			<13410 13311 13301 13281 13273 13271>,
			<13431 13310 13302 13281 13273 13271>,
			<13453 13311 13301 13281 13273 13271>,
			<13476 13317 13299 13282 13273 13270>,
			<13502 13321 13299 13282 13273 13270>,
			<13531 13325 13301 13282 13273 13271>,
			<13562 13327 13302 13283 13274 13272>,
			<13599 13331 13303 13282 13273 13271>,
			<13641 13335 13303 13280 13272 13270>,
			<13685 13338 13303 13280 13271 13269>,
			<13728 13341 13305 13280 13271 13270>,
			<13773 13343 13306 13280 13272 13271>,
			<13817 13350 13307 13280 13272 13271>,
			<13862 13366 13307 13280 13273 13272>,
			<13914 13383 13308 13281 13273 13271>,
			<13972 13408 13309 13282 13272 13271>,
			<14024 13456 13313 13283 13274 13273>,
			<13994 13459 13315 13282 13276 13275>,
			<14057 13501 13319 13287 13278 13277>,
			<14121 13558 13327 13289 13281 13278>,
			<14189 13623 13335 13292 13281 13277>,
			<14272 13701 13337 13288 13277 13275>,
			<14379 13807 13340 13290 13279 13275>,
			<14558 13971 13353 13293 13281 13278>,
			<14929 14177 13380 13298 13283 13281>,
			<14929 14177 13380 13298 13283 13281>,
			<14929 14177 13380 13298 13283 13281>;
	};

	qcom,pc-temp-y4-lut {
		qcom,lut-col-legend = <(-10) 0 10 25 40 50>;
		qcom,lut-row-legend = <10000 9800 9600 9400 9200 9000>,
			<8800 8600 8400 8200 8000 7800>,
			<7600 7400 7200 7000 6800 6600>,
			<6400 6200 6000 5800 5600 5400>,
			<5200 5000 4800 4600 4400 4200>,
			<4000 3800 3600 3400 3200 3000>,
			<2800 2600 2400 2200 2000 1800>,
			<1600 1400 1200 1000 900 800>,
			<700 600 500 400 300 200>,
			<100 0>;
		qcom,lut-data = <16823 16633 16535 16475 16444 16449>,
			<16920 16645 16532 16466 16444 16445>,
			<16991 16660 16530 16460 16444 16442>,
			<17039 16677 16529 16457 16443 16440>,
			<17066 16690 16529 16456 16444 16438>,
			<17074 16698 16529 16455 16444 16438>,
			<17052 16701 16529 16457 16444 16438>,
			<17013 16703 16531 16460 16445 16439>,
			<17016 16704 16533 16464 16446 16440>,
			<17108 16702 16538 16468 16449 16441>,
			<17227 16701 16545 16473 16451 16443>,
			<17350 16736 16551 16478 16452 16445>,
			<17472 16809 16559 16484 16452 16447>,
			<17462 16855 16576 16490 16453 16449>,
			<17127 16887 16620 16495 16458 16451>,
			<16847 16904 16655 16502 16465 16453>,
			<16856 16847 16665 16514 16471 16457>,
			<16893 16719 16671 16530 16477 16465>,
			<16902 16668 16667 16547 16489 16475>,
			<16869 16660 16626 16570 16512 16491>,
			<16822 16653 16578 16582 16527 16501>,
			<16774 16635 16545 16551 16509 16488>,
			<16722 16609 16516 16493 16474 16463>,
			<16700 16590 16502 16467 16456 16451>,
			<16693 16579 16495 16455 16448 16445>,
			<16690 16569 16491 16450 16444 16442>,
			<16692 16553 16491 16451 16444 16442>,
			<16699 16535 16491 16453 16445 16442>,
			<16702 16529 16491 16455 16446 16443>,
			<16699 16533 16492 16459 16450 16446>,
			<16695 16537 16492 16463 16455 16450>,
			<16696 16539 16490 16469 16462 16456>,
			<16700 16539 16486 16474 16469 16464>,
			<16704 16541 16485 16475 16473 16468>,
			<16710 16548 16489 16475 16475 16471>,
			<16715 16558 16495 16475 16477 16472>,
			<16719 16569 16500 16470 16467 16465>,
			<16724 16581 16504 16459 16447 16447>,
			<16725 16594 16507 16455 16442 16441>,
			<16722 16613 16509 16454 16442 16441>,
			<16718 16631 16511 16453 16443 16441>,
			<16717 16637 16514 16455 16443 16441>,
			<16717 16640 16517 16458 16443 16441>,
			<16719 16639 16521 16457 16440 16436>,
			<16730 16636 16527 16456 16438 16431>,
			<16752 16642 16528 16458 16441 16435>,
			<16741 16643 16530 16466 16449 16446>,
			<16758 16664 16548 16474 16462 16468>,
			<16780 16694 16574 16492 16488 16492>,
			<16801 16734 16606 16507 16483 16476>,
			<16800 16763 16605 16478 16452 16443>,
			<16778 16763 16598 16477 16446 16440>,
			<16772 16779 16619 16490 16450 16444>,
			<16853 16819 16673 16521 16468 16462>,
			<16853 16819 16673 16521 16468 16462>,
			<16853 16819 16673 16521 16468 16462>;
	};

	qcom,pc-temp-y5-lut {
		qcom,lut-col-legend = <(-10) 0 10 25 40 50>;
		qcom,lut-row-legend = <10000 9800 9600 9400 9200 9000>,
			<8800 8600 8400 8200 8000 7800>,
			<7600 7400 7200 7000 6800 6600>,
			<6400 6200 6000 5800 5600 5400>,
			<5200 5000 4800 4600 4400 4200>,
			<4000 3800 3600 3400 3200 3000>,
			<2800 2600 2400 2200 2000 1800>,
			<1600 1400 1200 1000 900 800>,
			<700 600 500 400 300 200>,
			<100 0>;
		qcom,lut-data = <15081 17463 19046 16729 19511 13734>,
			<13778 17721 19729 18107 19110 16441>,
			<13190 17987 20144 18964 18711 18383>,
			<13170 18221 20359 19423 18339 19654>,
			<13571 18380 20439 19608 18018 20351>,
			<14244 18424 20451 19641 17773 20568>,
			<16369 18300 20186 19140 17620 20006>,
			<19287 18119 19622 18163 17491 18974>,
			<19415 18364 19112 17434 17252 18439>,
			<15573 20362 18604 16799 16795 18173>,
			<12614 21900 18117 16263 16522 17913>,
			<14079 19916 17621 15772 17305 17470>,
			<17451 16058 17146 15379 18618 17020>,
			<19901 15300 16826 15369 18753 17077>,
			<21890 18198 16455 15724 17766 18044>,
			<23000 21219 16239 15994 17052 18757>,
			<20729 22545 17463 16015 17072 18073>,
			<15810 23487 20065 16019 17147 16830>,
			<14290 23671 21862 16369 17241 16554>,
			<14768 23217 23294 18468 17443 16848>,
			<15205 22745 24047 20775 17771 17337>,
			<15091 22609 23962 22602 18789 18572>,
			<14688 22538 23748 24136 20217 20289>,
			<14254 22511 23491 24430 20556 20708>,
			<13727 22326 22617 24197 20397 20534>,
			<13230 21950 21883 23846 20266 20389>,
			<12883 20822 21420 23251 20523 20216>,
			<12584 18527 20728 22503 21006 19877>,
			<12501 17062 20904 22136 21053 19773>,
			<12711 16223 22776 21780 20444 19693>,
			<13000 15699 24293 21658 19962 19542>,
			<13172 16051 23631 22118 19906 19154>,
			<13306 17382 22124 22983 19884 18591>,
			<13425 18527 21787 23988 20285 18630>,
			<13525 19257 23229 25520 22034 20584>,
			<13626 19906 24513 26464 23386 22278>,
			<13799 20665 24267 25667 23014 21975>,
			<14066 21569 23518 23991 22069 21190>,
			<14183 21900 22993 22962 21378 20963>,
			<14105 19200 22614 22157 20777 21252>,
			<13947 15658 22201 21488 20351 21548>,
			<13683 14886 21432 20892 20251 21536>,
			<13277 14705 20234 20425 20318 21492>,
			<13294 14434 19227 20367 20672 22177>,
			<13487 14126 18403 20603 20567 22347>,
			<13361 13991 18402 20305 18736 20547>,
			<13332 13979 18564 18440 19762 20929>,
			<13546 13868 18451 20466 19376 20443>,
			<14018 14347 18853 19961 19431 18445>,
			<14237 14512 19187 20386 18980 18741>,
			<14397 14750 19069 20462 18868 20097>,
			<13809 14678 18491 21937 22887 20874>,
			<13891 14159 17881 22489 24644 23727>,
			<13146 13822 16027 23827 25819 27040>,
			<13146 13822 16027 23827 25819 27040>,
			<13146 13822 16027 23827 25819 27040>;
	};

	qcom,pc-temp-y6-lut {
		qcom,lut-col-legend = <(-10) 0 10 25 40 50>;
		qcom,lut-row-legend = <10000 9800 9600 9400 9200 9000>,
			<8800 8600 8400 8200 8000 7800>,
			<7600 7400 7200 7000 6800 6600>,
			<6400 6200 6000 5800 5600 5400>,
			<5200 5000 4800 4600 4400 4200>,
			<4000 3800 3600 3400 3200 3000>,
			<2800 2600 2400 2200 2000 1800>,
			<1600 1400 1200 1000 900 800>,
			<700 600 500 400 300 200>,
			<100 0>;
		qcom,lut-data = <5849 5304 5090 4980 4956 4950>,
			<5845 5303 5089 4980 4956 4950>,
			<5838 5302 5088 4980 4956 4950>,
			<5830 5301 5086 4980 4956 4950>,
			<5824 5300 5085 4980 4956 4951>,
			<5821 5299 5084 4980 4956 4951>,
			<5821 5297 5082 4980 4956 4951>,
			<5821 5294 5081 4981 4957 4951>,
			<5818 5294 5080 4982 4958 4952>,
			<5796 5294 5081 4983 4958 4952>,
			<5778 5296 5081 4984 4959 4953>,
			<5801 5301 5083 4986 4961 4954>,
			<5844 5310 5085 4988 4962 4955>,
			<5848 5316 5090 4990 4964 4956>,
			<5772 5321 5102 4994 4966 4958>,
			<5699 5323 5111 4998 4968 4960>,
			<5681 5308 5113 5002 4970 4961>,
			<5670 5274 5114 5005 4972 4963>,
			<5663 5257 5112 5010 4976 4965>,
			<5658 5252 5098 5017 4982 4970>,
			<5654 5247 5081 5021 4986 4974>,
			<5648 5240 5070 5011 4980 4969>,
			<5641 5231 5060 4991 4966 4959>,
			<5639 5226 5055 4982 4960 4954>,
			<5645 5224 5052 4978 4957 4952>,
			<5654 5222 5051 4977 4955 4951>,
			<5664 5220 5051 4977 4955 4951>,
			<5679 5218 5051 4977 4956 4951>,
			<5695 5217 5052 4978 4957 4951>,
			<5713 5222 5055 4979 4958 4953>,
			<5734 5231 5058 4981 4960 4954>,
			<5756 5240 5058 4983 4962 4956>,
			<5781 5252 5057 4985 4964 4958>,
			<5807 5266 5058 4987 4965 4959>,
			<5836 5282 5062 4987 4967 4960>,
			<5867 5300 5067 4988 4967 4961>,
			<5901 5320 5071 4986 4964 4959>,
			<5937 5342 5074 4982 4958 4953>,
			<5974 5365 5078 4981 4956 4951>,
			<6010 5387 5083 4981 4956 4951>,
			<6047 5410 5088 4981 4957 4952>,
			<6083 5439 5095 4982 4958 4953>,
			<6119 5476 5103 4984 4958 4953>,
			<6160 5520 5114 4984 4957 4951>,
			<6209 5574 5129 4986 4957 4950>,
			<6261 5642 5140 4988 4959 4953>,
			<6249 5650 5145 4990 4963 4958>,
			<6300 5702 5163 4996 4968 4966>,
			<6359 5769 5188 5003 4978 4973>,
			<6422 5844 5215 5009 4976 4968>,
			<6492 5927 5231 4999 4965 4958>,
			<6578 6027 5256 5001 4965 4957>,
			<6732 6178 5320 5010 4969 4961>,
			<7106 6366 5407 5025 4976 4969>,
			<7106 6366 5407 5025 4976 4969>,
			<7106 6366 5407 5025 4976 4969>;
	};

};
